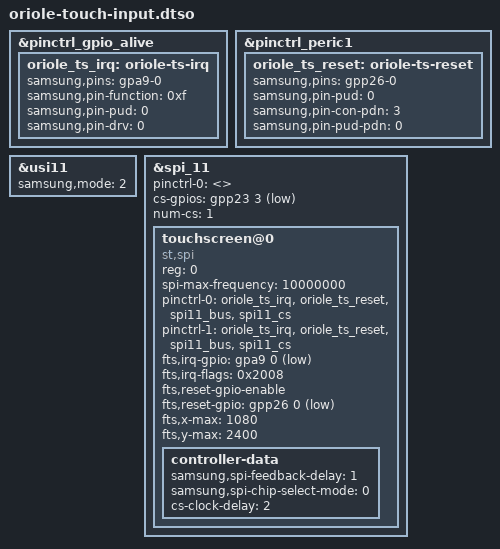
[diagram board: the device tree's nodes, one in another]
// SPDX-License-Identifier: GPL-2.0-only
// Experimental oriole input-only stage; GS101 pins from GPL gs101-mainline.
/dts-v1/;
/plugin/;
&pinctrl_gpio_alive {
 oriole_ts_irq: oriole-ts-irq {
  samsung,pins = "gpa9-0";
  samsung,pin-function = <0xf>;
  samsung,pin-pud = <0>;
  samsung,pin-drv = <0>;
 };
};
&pinctrl_peric1 {
 oriole_ts_reset: oriole-ts-reset {
  samsung,pins = "gpp26-0";
  samsung,pin-pud = <0>;
  samsung,pin-con-pdn = <3>;
  samsung,pin-pud-pdn = <0>;
 };
};
&usi11 { samsung,mode = <2>; status = "okay"; };
&spi_11 {
 #address-cells = <1>;
 #size-cells = <0>;
 status = "okay";
 pinctrl-0 = <>;
 cs-gpios = <&gpp23 3 1>;
 num-cs = <1>;
 touchscreen@0 {
  compatible = "st,spi";
  reg = <0>;
  spi-max-frequency = <10000000>;
  pinctrl-names = "pmx_ts_active", "pmx_ts_suspend";
  pinctrl-0 = <&oriole_ts_irq &oriole_ts_reset &spi11_bus &spi11_cs>;
  pinctrl-1 = <&oriole_ts_irq &oriole_ts_reset &spi11_bus &spi11_cs>;
  fts,irq-gpio = <&gpa9 0 1>;
  fts,irq-flags = <0x2008>;
  fts,reset-gpio-enable;
  fts,reset-gpio = <&gpp26 0 1>;
  fts,x-max = <1080>;
  fts,y-max = <2400>;
  controller-data {
   samsung,spi-feedback-delay = <1>;
   samsung,spi-chip-select-mode = <0>;
   cs-clock-delay = <2>;
  };
 };
};
